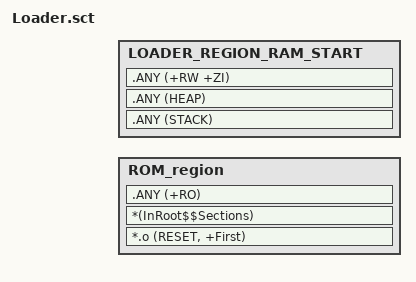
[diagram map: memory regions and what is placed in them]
#! armclang --target=arm-arm-none-eabi  -mcpu=cortex-m7 -E -xc
; *************************************************************
; *** Scatter-Loading Description File generated by uVision ***
; *************************************************************
#include "..\..\Linker_Common\MDK-ARM\mapping_sbsfu.h"
#include "..\..\Linker_Common\MDK-ARM\mapping_fwimg.h"


LR_ROM (APP_LOADER_REGION_RAM_CODE_START) {
  ROM_region (APP_LOADER_REGION_RAM_CODE_START) (APP_LOADER_RAM_CODE_REGION_SIZE){
  *.o (RESET, +First)
  *(InRoot$$Sections)
  .ANY (+RO)
  }
  
  LOADER_REGION_RAM_START (LOADER_REGION_RAM_START) {
  .ANY (STACK)
  .ANY (HEAP)
  .ANY (+RW +ZI)
  }
}
